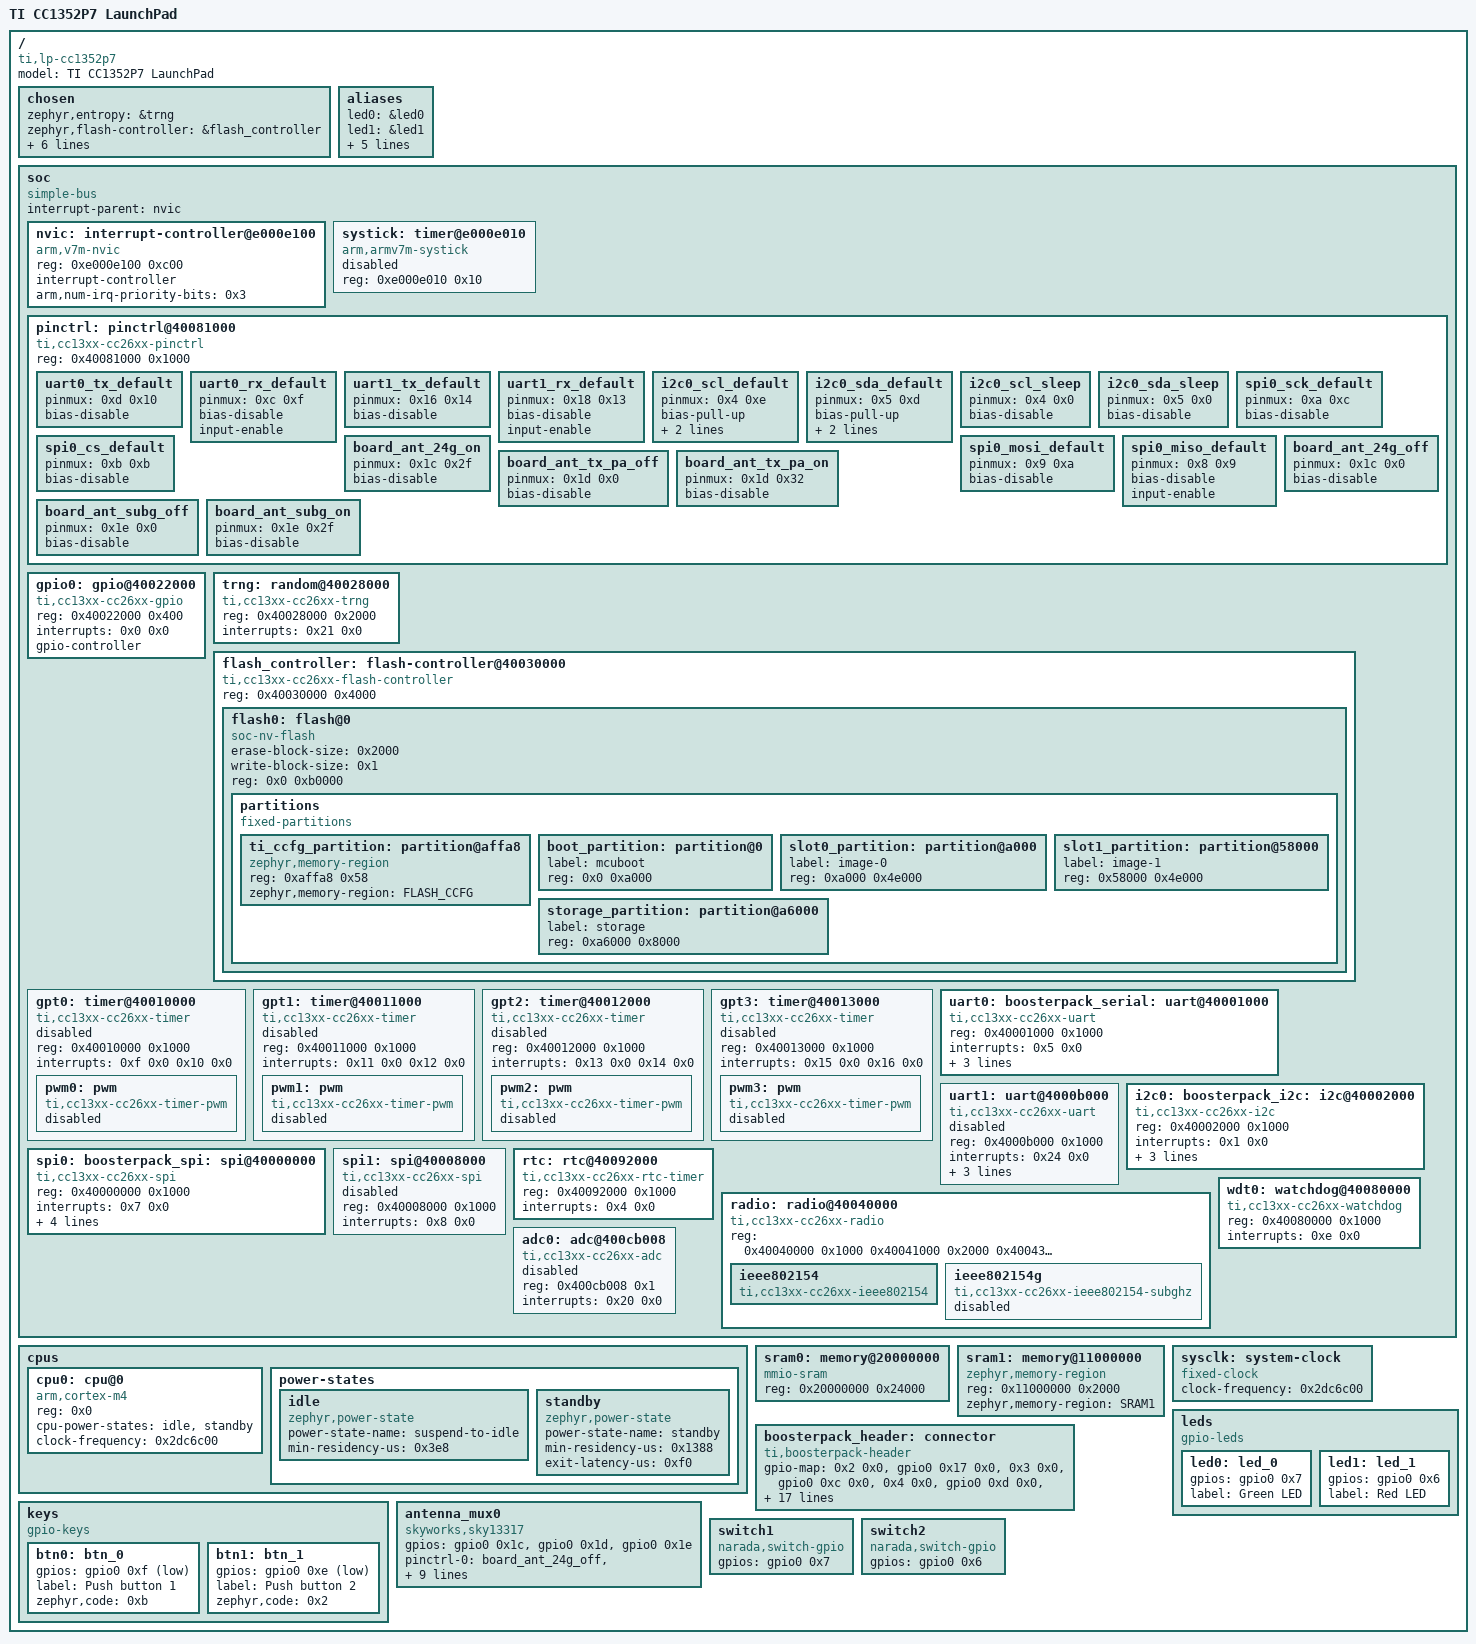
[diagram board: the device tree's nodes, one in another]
/dts-v1/;

/* node '/' defined in zephyr/dts/common/skeleton.dtsi:9 */
/ {
	#address-cells = < 0x1 >;        /* in zephyr/dts/common/skeleton.dtsi:10 */
	#size-cells = < 0x1 >;           /* in zephyr/dts/common/skeleton.dtsi:11 */
	model = "TI CC1352P7 LaunchPad"; /* in zephyr/boards/ti/cc1352p7_launchpad/cc1352p7_lp.dts:15 */
	compatible = "ti,lp-cc1352p7";   /* in zephyr/boards/ti/cc1352p7_launchpad/cc1352p7_lp.dts:16 */

	/* node '/chosen' defined in zephyr/dts/common/skeleton.dtsi:12 */
	chosen {
		zephyr,entropy = &trng;                      /* in zephyr/dts/arm/ti/cc13xx_cc26xx.dtsi:15 */
		zephyr,flash-controller = &flash_controller; /* in zephyr/dts/arm/ti/cc13xx_cc26xx.dtsi:16 */
		zephyr,sram = &sram0;                        /* in zephyr/boards/ti/common/launchxl.dtsi:25 */
		zephyr,flash = &flash0;                      /* in zephyr/boards/ti/common/launchxl.dtsi:26 */
		zephyr,console = &uart0;                     /* in zephyr/boards/ti/common/launchxl.dtsi:27 */
		zephyr,shell-uart = &uart0;                  /* in zephyr/boards/ti/common/launchxl.dtsi:28 */
		zephyr,ieee802154 = &ieee802154;             /* in zephyr/boards/ti/common/launchxl.dtsi:29 */
		zephyr,code-partition = &slot0_partition;    /* in zephyr/boards/ti/common/launchxl.dtsi:30 */
	};

	/* node '/aliases' defined in zephyr/dts/common/skeleton.dtsi:13 */
	aliases {
		led0 = &led0;            /* in zephyr/boards/ti/common/launchxl.dtsi:15 */
		led1 = &led1;            /* in zephyr/boards/ti/common/launchxl.dtsi:16 */
		sw0 = &btn0;             /* in zephyr/boards/ti/common/launchxl.dtsi:17 */
		sw1 = &btn1;             /* in zephyr/boards/ti/common/launchxl.dtsi:18 */
		watchdog0 = &wdt0;       /* in zephyr/boards/ti/common/launchxl.dtsi:19 */
		mcuboot-led0 = &led1;    /* in zephyr/boards/ti/common/launchxl.dtsi:20 */
		mcuboot-button0 = &btn1; /* in zephyr/boards/ti/common/launchxl.dtsi:21 */
	};

	/* node '/soc' defined in zephyr/dts/arm/armv7-m.dtsi:6 */
	soc {
		#address-cells = < 0x1 >;     /* in zephyr/dts/arm/armv7-m.dtsi:7 */
		#size-cells = < 0x1 >;        /* in zephyr/dts/arm/armv7-m.dtsi:8 */
		compatible = "simple-bus";    /* in zephyr/dts/arm/armv7-m.dtsi:9 */
		interrupt-parent = < &nvic >; /* in zephyr/dts/arm/armv7-m.dtsi:10 */
		ranges;                       /* in zephyr/dts/arm/armv7-m.dtsi:11 */

		/* node '/soc/interrupt-controller@e000e100' defined in zephyr/dts/arm/armv7-m.dtsi:13 */
		nvic: interrupt-controller@e000e100 {
			#address-cells = < 0x1 >;            /* in zephyr/dts/arm/armv7-m.dtsi:14 */
			compatible = "arm,v7m-nvic";         /* in zephyr/dts/arm/armv7-m.dtsi:15 */
			reg = < 0xe000e100 0xc00 >;          /* in zephyr/dts/arm/armv7-m.dtsi:16 */
			interrupt-controller;                /* in zephyr/dts/arm/armv7-m.dtsi:17 */
			#interrupt-cells = < 0x2 >;          /* in zephyr/dts/arm/armv7-m.dtsi:18 */
			arm,num-irq-priority-bits = < 0x3 >; /* in zephyr/dts/arm/ti/cc13xx_cc26xx.dtsi:246 */
			phandle = < 0x1 >;                   /* in zephyr/dts/arm/armv7-m.dtsi:10 */
		};

		/* node '/soc/timer@e000e010' defined in zephyr/dts/arm/armv7-m.dtsi:21 */
		systick: timer@e000e010 {
			compatible = "arm,armv7m-systick"; /* in zephyr/dts/arm/armv7-m.dtsi:22 */
			reg = < 0xe000e010 0x10 >;         /* in zephyr/dts/arm/armv7-m.dtsi:23 */
			status = "disabled";               /* in zephyr/dts/arm/ti/cc13xx_cc26xx.dtsi:250 */
		};

		/* node '/soc/pinctrl@40081000' defined in zephyr/dts/arm/ti/cc13xx_cc26xx.dtsi:64 */
		pinctrl: pinctrl@40081000 {
			compatible = "ti,cc13xx-cc26xx-pinctrl"; /* in zephyr/dts/arm/ti/cc13xx_cc26xx.dtsi:65 */
			reg = < 0x40081000 0x1000 >;             /* in zephyr/dts/arm/ti/cc13xx_cc26xx.dtsi:66 */

			/* node '/soc/pinctrl@40081000/uart0_tx_default' defined in zephyr/boards/ti/common/launchxl-pinctrl.dtsi:11 */
			uart0_tx_default: uart0_tx_default {
				pinmux = < 0xd 0x10 >; /* in zephyr/boards/ti/common/launchxl-pinctrl.dtsi:12 */
				bias-disable;          /* in zephyr/boards/ti/common/launchxl-pinctrl.dtsi:13 */
				phandle = < 0x4 >;     /* in zephyr/boards/ti/common/launchxl.dtsi:75 */
			};

			/* node '/soc/pinctrl@40081000/uart0_rx_default' defined in zephyr/boards/ti/common/launchxl-pinctrl.dtsi:15 */
			uart0_rx_default: uart0_rx_default {
				pinmux = < 0xc 0xf >; /* in zephyr/boards/ti/common/launchxl-pinctrl.dtsi:16 */
				bias-disable;         /* in zephyr/boards/ti/common/launchxl-pinctrl.dtsi:17 */
				input-enable;         /* in zephyr/boards/ti/common/launchxl-pinctrl.dtsi:18 */
				phandle = < 0x3 >;    /* in zephyr/boards/ti/common/launchxl.dtsi:75 */
			};

			/* node '/soc/pinctrl@40081000/uart1_tx_default' defined in zephyr/boards/ti/common/launchxl-pinctrl.dtsi:22 */
			uart1_tx_default: uart1_tx_default {
				pinmux = < 0x16 0x14 >; /* in zephyr/boards/ti/common/launchxl-pinctrl.dtsi:23 */
				bias-disable;           /* in zephyr/boards/ti/common/launchxl-pinctrl.dtsi:24 */
				phandle = < 0x6 >;      /* in zephyr/boards/ti/common/launchxl.dtsi:82 */
			};

			/* node '/soc/pinctrl@40081000/uart1_rx_default' defined in zephyr/boards/ti/common/launchxl-pinctrl.dtsi:26 */
			uart1_rx_default: uart1_rx_default {
				pinmux = < 0x18 0x13 >; /* in zephyr/boards/ti/common/launchxl-pinctrl.dtsi:27 */
				bias-disable;           /* in zephyr/boards/ti/common/launchxl-pinctrl.dtsi:28 */
				input-enable;           /* in zephyr/boards/ti/common/launchxl-pinctrl.dtsi:29 */
				phandle = < 0x5 >;      /* in zephyr/boards/ti/common/launchxl.dtsi:82 */
			};

			/* node '/soc/pinctrl@40081000/i2c0_scl_default' defined in zephyr/boards/ti/common/launchxl-pinctrl.dtsi:33 */
			i2c0_scl_default: i2c0_scl_default {
				pinmux = < 0x4 0xe >; /* in zephyr/boards/ti/common/launchxl-pinctrl.dtsi:34 */
				bias-pull-up;         /* in zephyr/boards/ti/common/launchxl-pinctrl.dtsi:35 */
				drive-open-drain;     /* in zephyr/boards/ti/common/launchxl-pinctrl.dtsi:36 */
				input-enable;         /* in zephyr/boards/ti/common/launchxl-pinctrl.dtsi:37 */
				phandle = < 0x7 >;    /* in zephyr/boards/ti/common/launchxl.dtsi:88 */
			};

			/* node '/soc/pinctrl@40081000/i2c0_sda_default' defined in zephyr/boards/ti/common/launchxl-pinctrl.dtsi:39 */
			i2c0_sda_default: i2c0_sda_default {
				pinmux = < 0x5 0xd >; /* in zephyr/boards/ti/common/launchxl-pinctrl.dtsi:40 */
				bias-pull-up;         /* in zephyr/boards/ti/common/launchxl-pinctrl.dtsi:41 */
				drive-open-drain;     /* in zephyr/boards/ti/common/launchxl-pinctrl.dtsi:42 */
				input-enable;         /* in zephyr/boards/ti/common/launchxl-pinctrl.dtsi:43 */
				phandle = < 0x8 >;    /* in zephyr/boards/ti/common/launchxl.dtsi:88 */
			};

			/* node '/soc/pinctrl@40081000/i2c0_scl_sleep' defined in zephyr/boards/ti/common/launchxl-pinctrl.dtsi:45 */
			i2c0_scl_sleep: i2c0_scl_sleep {
				pinmux = < 0x4 0x0 >; /* in zephyr/boards/ti/common/launchxl-pinctrl.dtsi:46 */
				bias-disable;         /* in zephyr/boards/ti/common/launchxl-pinctrl.dtsi:47 */
				phandle = < 0x9 >;    /* in zephyr/boards/ti/common/launchxl.dtsi:89 */
			};

			/* node '/soc/pinctrl@40081000/i2c0_sda_sleep' defined in zephyr/boards/ti/common/launchxl-pinctrl.dtsi:49 */
			i2c0_sda_sleep: i2c0_sda_sleep {
				pinmux = < 0x5 0x0 >; /* in zephyr/boards/ti/common/launchxl-pinctrl.dtsi:50 */
				bias-disable;         /* in zephyr/boards/ti/common/launchxl-pinctrl.dtsi:51 */
				phandle = < 0xa >;    /* in zephyr/boards/ti/common/launchxl.dtsi:89 */
			};

			/* node '/soc/pinctrl@40081000/spi0_sck_default' defined in zephyr/boards/ti/common/launchxl-pinctrl.dtsi:55 */
			spi0_sck_default: spi0_sck_default {
				pinmux = < 0xa 0xc >; /* in zephyr/boards/ti/common/launchxl-pinctrl.dtsi:56 */
				bias-disable;         /* in zephyr/boards/ti/common/launchxl-pinctrl.dtsi:57 */
				phandle = < 0xb >;    /* in zephyr/boards/ti/common/launchxl.dtsi:95 */
			};

			/* node '/soc/pinctrl@40081000/spi0_mosi_default' defined in zephyr/boards/ti/common/launchxl-pinctrl.dtsi:59 */
			spi0_mosi_default: spi0_mosi_default {
				pinmux = < 0x9 0xa >; /* in zephyr/boards/ti/common/launchxl-pinctrl.dtsi:60 */
				bias-disable;         /* in zephyr/boards/ti/common/launchxl-pinctrl.dtsi:61 */
				phandle = < 0xc >;    /* in zephyr/boards/ti/common/launchxl.dtsi:95 */
			};

			/* node '/soc/pinctrl@40081000/spi0_miso_default' defined in zephyr/boards/ti/common/launchxl-pinctrl.dtsi:63 */
			spi0_miso_default: spi0_miso_default {
				pinmux = < 0x8 0x9 >; /* in zephyr/boards/ti/common/launchxl-pinctrl.dtsi:64 */
				bias-disable;         /* in zephyr/boards/ti/common/launchxl-pinctrl.dtsi:65 */
				input-enable;         /* in zephyr/boards/ti/common/launchxl-pinctrl.dtsi:66 */
				phandle = < 0xd >;    /* in zephyr/boards/ti/common/launchxl.dtsi:95 */
			};

			/* node '/soc/pinctrl@40081000/spi0_cs_default' defined in zephyr/boards/ti/common/launchxl-pinctrl.dtsi:68 */
			spi0_cs_default: spi0_cs_default {
				pinmux = < 0xb 0xb >; /* in zephyr/boards/ti/common/launchxl-pinctrl.dtsi:69 */
				bias-disable;         /* in zephyr/boards/ti/common/launchxl-pinctrl.dtsi:70 */
				phandle = < 0xe >;    /* in zephyr/boards/ti/common/launchxl.dtsi:95 */
			};

			/* node '/soc/pinctrl@40081000/board_ant_24g_off' defined in zephyr/boards/ti/common/launchxl_sky13317.dtsi:37 */
			board_ant_24g_off: board_ant_24g_off {
				pinmux = < 0x1c 0x0 >; /* in zephyr/boards/ti/common/launchxl_sky13317.dtsi:38 */
				bias-disable;          /* in zephyr/boards/ti/common/launchxl_sky13317.dtsi:39 */
				phandle = < 0x12 >;    /* in zephyr/boards/ti/common/launchxl_sky13317.dtsi:26 */
			};

			/* node '/soc/pinctrl@40081000/board_ant_24g_on' defined in zephyr/boards/ti/common/launchxl_sky13317.dtsi:41 */
			board_ant_24g_on: board_ant_24g_on {
				pinmux = < 0x1c 0x2f >; /* in zephyr/boards/ti/common/launchxl_sky13317.dtsi:42 */
				bias-disable;           /* in zephyr/boards/ti/common/launchxl_sky13317.dtsi:43 */
				phandle = < 0x15 >;     /* in zephyr/boards/ti/common/launchxl_sky13317.dtsi:27 */
			};

			/* node '/soc/pinctrl@40081000/board_ant_tx_pa_off' defined in zephyr/boards/ti/common/launchxl_sky13317.dtsi:45 */
			board_ant_tx_pa_off: board_ant_tx_pa_off {
				pinmux = < 0x1d 0x0 >; /* in zephyr/boards/ti/common/launchxl_sky13317.dtsi:46 */
				bias-disable;          /* in zephyr/boards/ti/common/launchxl_sky13317.dtsi:47 */
				phandle = < 0x13 >;    /* in zephyr/boards/ti/common/launchxl_sky13317.dtsi:26 */
			};

			/* node '/soc/pinctrl@40081000/board_ant_tx_pa_on' defined in zephyr/boards/ti/common/launchxl_sky13317.dtsi:49 */
			board_ant_tx_pa_on: board_ant_tx_pa_on {
				pinmux = < 0x1d 0x32 >; /* in zephyr/boards/ti/common/launchxl_sky13317.dtsi:50 */
				bias-disable;           /* in zephyr/boards/ti/common/launchxl_sky13317.dtsi:51 */
				phandle = < 0x16 >;     /* in zephyr/boards/ti/common/launchxl_sky13317.dtsi:28 */
			};

			/* node '/soc/pinctrl@40081000/board_ant_subg_off' defined in zephyr/boards/ti/common/launchxl_sky13317.dtsi:53 */
			board_ant_subg_off: board_ant_subg_off {
				pinmux = < 0x1e 0x0 >; /* in zephyr/boards/ti/common/launchxl_sky13317.dtsi:54 */
				bias-disable;          /* in zephyr/boards/ti/common/launchxl_sky13317.dtsi:55 */
				phandle = < 0x14 >;    /* in zephyr/boards/ti/common/launchxl_sky13317.dtsi:26 */
			};

			/* node '/soc/pinctrl@40081000/board_ant_subg_on' defined in zephyr/boards/ti/common/launchxl_sky13317.dtsi:57 */
			board_ant_subg_on: board_ant_subg_on {
				pinmux = < 0x1e 0x2f >; /* in zephyr/boards/ti/common/launchxl_sky13317.dtsi:58 */
				bias-disable;           /* in zephyr/boards/ti/common/launchxl_sky13317.dtsi:59 */
				phandle = < 0x17 >;     /* in zephyr/boards/ti/common/launchxl_sky13317.dtsi:29 */
			};
		};

		/* node '/soc/gpio@40022000' defined in zephyr/dts/arm/ti/cc13xx_cc26xx.dtsi:69 */
		gpio0: gpio@40022000 {
			compatible = "ti,cc13xx-cc26xx-gpio"; /* in zephyr/dts/arm/ti/cc13xx_cc26xx.dtsi:70 */
			reg = < 0x40022000 0x400 >;           /* in zephyr/dts/arm/ti/cc13xx_cc26xx.dtsi:71 */
			interrupts = < 0x0 0x0 >;             /* in zephyr/dts/arm/ti/cc13xx_cc26xx.dtsi:72 */
			status = "okay";                      /* in zephyr/boards/ti/common/launchxl.dtsi:69 */
			gpio-controller;                      /* in zephyr/dts/arm/ti/cc13xx_cc26xx.dtsi:74 */
			#gpio-cells = < 0x2 >;                /* in zephyr/dts/arm/ti/cc13xx_cc26xx.dtsi:75 */
			phandle = < 0xf >;                    /* in zephyr/boards/ti/common/launchxl.dtsi:98 */
		};

		/* node '/soc/random@40028000' defined in zephyr/dts/arm/ti/cc13xx_cc26xx.dtsi:78 */
		trng: random@40028000 {
			compatible = "ti,cc13xx-cc26xx-trng"; /* in zephyr/dts/arm/ti/cc13xx_cc26xx.dtsi:79 */
			reg = < 0x40028000 0x2000 >;          /* in zephyr/dts/arm/ti/cc13xx_cc26xx.dtsi:80 */
			interrupts = < 0x21 0x0 >;            /* in zephyr/dts/arm/ti/cc13xx_cc26xx.dtsi:81 */
			status = "okay";                      /* in zephyr/boards/ti/common/launchxl.dtsi:65 */
		};

		/* node '/soc/flash-controller@40030000' defined in zephyr/dts/arm/ti/cc13xx_cc26xx.dtsi:85 */
		flash_controller: flash-controller@40030000 {
			compatible = "ti,cc13xx-cc26xx-flash-controller"; /* in zephyr/dts/arm/ti/cc13xx_cc26xx.dtsi:86 */
			reg = < 0x40030000 0x4000 >;                      /* in zephyr/dts/arm/ti/cc13xx_cc26xx.dtsi:87 */
			#address-cells = < 0x1 >;                         /* in zephyr/dts/arm/ti/cc13xx_cc26xx.dtsi:89 */
			#size-cells = < 0x1 >;                            /* in zephyr/dts/arm/ti/cc13xx_cc26xx.dtsi:90 */

			/* node '/soc/flash-controller@40030000/flash@0' defined in zephyr/dts/arm/ti/cc13xx_cc26xx.dtsi:92 */
			flash0: flash@0 {
				compatible = "soc-nv-flash";   /* in zephyr/dts/arm/ti/cc13xx_cc26xx.dtsi:93 */
				erase-block-size = < 0x2000 >; /* in zephyr/dts/arm/ti/cc13xx_cc26xx.dtsi:94 */
				write-block-size = < 0x1 >;    /* in zephyr/dts/arm/ti/cc13xx_cc26xx.dtsi:95 */
				reg = < 0x0 0xb0000 >;         /* in zephyr/dts/arm/ti/cc1352r7.dtsi:17 */

				/* node '/soc/flash-controller@40030000/flash@0/partitions' defined in zephyr/dts/arm/ti/cc1352r7.dtsi:19 */
				partitions {
					compatible = "fixed-partitions"; /* in zephyr/dts/arm/ti/cc1352r7.dtsi:20 */
					#address-cells = < 0x1 >;        /* in zephyr/dts/arm/ti/cc1352r7.dtsi:21 */
					#size-cells = < 0x1 >;           /* in zephyr/dts/arm/ti/cc1352r7.dtsi:22 */

					/* node '/soc/flash-controller@40030000/flash@0/partitions/partition@affa8' defined in zephyr/dts/arm/ti/cc1352r7.dtsi:25 */
					ti_ccfg_partition: partition@affa8 {
						compatible = "zephyr,memory-region"; /* in zephyr/dts/arm/ti/cc1352r7.dtsi:26 */
						reg = < 0xaffa8 0x58 >;              /* in zephyr/dts/arm/ti/cc1352r7.dtsi:27 */
						zephyr,memory-region = "FLASH_CCFG"; /* in zephyr/dts/arm/ti/cc1352r7.dtsi:28 */
					};

					/* node '/soc/flash-controller@40030000/flash@0/partitions/partition@0' defined in zephyr/boards/ti/common/launchxl-flash-p7.dtsi:10 */
					boot_partition: partition@0 {
						label = "mcuboot";    /* in zephyr/boards/ti/common/launchxl-flash-p7.dtsi:11 */
						reg = < 0x0 0xa000 >; /* in zephyr/boards/ti/common/launchxl-flash-p7.dtsi:12 */
					};

					/* node '/soc/flash-controller@40030000/flash@0/partitions/partition@a000' defined in zephyr/boards/ti/common/launchxl-flash-p7.dtsi:16 */
					slot0_partition: partition@a000 {
						label = "image-0";        /* in zephyr/boards/ti/common/launchxl-flash-p7.dtsi:17 */
						reg = < 0xa000 0x4e000 >; /* in zephyr/boards/ti/common/launchxl-flash-p7.dtsi:18 */
					};

					/* node '/soc/flash-controller@40030000/flash@0/partitions/partition@58000' defined in zephyr/boards/ti/common/launchxl-flash-p7.dtsi:21 */
					slot1_partition: partition@58000 {
						label = "image-1";         /* in zephyr/boards/ti/common/launchxl-flash-p7.dtsi:22 */
						reg = < 0x58000 0x4e000 >; /* in zephyr/boards/ti/common/launchxl-flash-p7.dtsi:23 */
					};

					/* node '/soc/flash-controller@40030000/flash@0/partitions/partition@a6000' defined in zephyr/boards/ti/common/launchxl-flash-p7.dtsi:27 */
					storage_partition: partition@a6000 {
						label = "storage";        /* in zephyr/boards/ti/common/launchxl-flash-p7.dtsi:28 */
						reg = < 0xa6000 0x8000 >; /* in zephyr/boards/ti/common/launchxl-flash-p7.dtsi:29 */
					};
				};
			};
		};

		/* node '/soc/timer@40010000' defined in zephyr/dts/arm/ti/cc13xx_cc26xx.dtsi:99 */
		gpt0: timer@40010000 {
			compatible = "ti,cc13xx-cc26xx-timer"; /* in zephyr/dts/arm/ti/cc13xx_cc26xx.dtsi:100 */
			reg = < 0x40010000 0x1000 >;           /* in zephyr/dts/arm/ti/cc13xx_cc26xx.dtsi:101 */
			interrupts = < 0xf 0x0 0x10 0x0 >;     /* in zephyr/dts/arm/ti/cc13xx_cc26xx.dtsi:102 */
			interrupt-names = "gpt0a",
			                  "gpt0b";             /* in zephyr/dts/arm/ti/cc13xx_cc26xx.dtsi:103 */
			status = "disabled";                   /* in zephyr/dts/arm/ti/cc13xx_cc26xx.dtsi:104 */

			/* node '/soc/timer@40010000/pwm' defined in zephyr/dts/arm/ti/cc13xx_cc26xx.dtsi:106 */
			pwm0: pwm {
				compatible = "ti,cc13xx-cc26xx-timer-pwm"; /* in zephyr/dts/arm/ti/cc13xx_cc26xx.dtsi:107 */
				#pwm-cells = < 0x3 >;                      /* in zephyr/dts/arm/ti/cc13xx_cc26xx.dtsi:108 */
				status = "disabled";                       /* in zephyr/dts/arm/ti/cc13xx_cc26xx.dtsi:109 */
			};
		};

		/* node '/soc/timer@40011000' defined in zephyr/dts/arm/ti/cc13xx_cc26xx.dtsi:113 */
		gpt1: timer@40011000 {
			compatible = "ti,cc13xx-cc26xx-timer"; /* in zephyr/dts/arm/ti/cc13xx_cc26xx.dtsi:114 */
			reg = < 0x40011000 0x1000 >;           /* in zephyr/dts/arm/ti/cc13xx_cc26xx.dtsi:115 */
			interrupts = < 0x11 0x0 0x12 0x0 >;    /* in zephyr/dts/arm/ti/cc13xx_cc26xx.dtsi:116 */
			interrupt-names = "gpt1a",
			                  "gpt1b";             /* in zephyr/dts/arm/ti/cc13xx_cc26xx.dtsi:117 */
			status = "disabled";                   /* in zephyr/dts/arm/ti/cc13xx_cc26xx.dtsi:118 */

			/* node '/soc/timer@40011000/pwm' defined in zephyr/dts/arm/ti/cc13xx_cc26xx.dtsi:120 */
			pwm1: pwm {
				compatible = "ti,cc13xx-cc26xx-timer-pwm"; /* in zephyr/dts/arm/ti/cc13xx_cc26xx.dtsi:121 */
				#pwm-cells = < 0x3 >;                      /* in zephyr/dts/arm/ti/cc13xx_cc26xx.dtsi:122 */
				status = "disabled";                       /* in zephyr/dts/arm/ti/cc13xx_cc26xx.dtsi:123 */
			};
		};

		/* node '/soc/timer@40012000' defined in zephyr/dts/arm/ti/cc13xx_cc26xx.dtsi:127 */
		gpt2: timer@40012000 {
			compatible = "ti,cc13xx-cc26xx-timer"; /* in zephyr/dts/arm/ti/cc13xx_cc26xx.dtsi:128 */
			reg = < 0x40012000 0x1000 >;           /* in zephyr/dts/arm/ti/cc13xx_cc26xx.dtsi:129 */
			interrupts = < 0x13 0x0 0x14 0x0 >;    /* in zephyr/dts/arm/ti/cc13xx_cc26xx.dtsi:130 */
			interrupt-names = "gpt2a",
			                  "gpt2b";             /* in zephyr/dts/arm/ti/cc13xx_cc26xx.dtsi:131 */
			status = "disabled";                   /* in zephyr/dts/arm/ti/cc13xx_cc26xx.dtsi:132 */

			/* node '/soc/timer@40012000/pwm' defined in zephyr/dts/arm/ti/cc13xx_cc26xx.dtsi:134 */
			pwm2: pwm {
				compatible = "ti,cc13xx-cc26xx-timer-pwm"; /* in zephyr/dts/arm/ti/cc13xx_cc26xx.dtsi:135 */
				#pwm-cells = < 0x3 >;                      /* in zephyr/dts/arm/ti/cc13xx_cc26xx.dtsi:136 */
				status = "disabled";                       /* in zephyr/dts/arm/ti/cc13xx_cc26xx.dtsi:137 */
			};
		};

		/* node '/soc/timer@40013000' defined in zephyr/dts/arm/ti/cc13xx_cc26xx.dtsi:141 */
		gpt3: timer@40013000 {
			compatible = "ti,cc13xx-cc26xx-timer"; /* in zephyr/dts/arm/ti/cc13xx_cc26xx.dtsi:142 */
			reg = < 0x40013000 0x1000 >;           /* in zephyr/dts/arm/ti/cc13xx_cc26xx.dtsi:143 */
			interrupts = < 0x15 0x0 0x16 0x0 >;    /* in zephyr/dts/arm/ti/cc13xx_cc26xx.dtsi:144 */
			interrupt-names = "gpt3a",
			                  "gpt3b";             /* in zephyr/dts/arm/ti/cc13xx_cc26xx.dtsi:145 */
			status = "disabled";                   /* in zephyr/dts/arm/ti/cc13xx_cc26xx.dtsi:146 */

			/* node '/soc/timer@40013000/pwm' defined in zephyr/dts/arm/ti/cc13xx_cc26xx.dtsi:148 */
			pwm3: pwm {
				compatible = "ti,cc13xx-cc26xx-timer-pwm"; /* in zephyr/dts/arm/ti/cc13xx_cc26xx.dtsi:149 */
				#pwm-cells = < 0x3 >;                      /* in zephyr/dts/arm/ti/cc13xx_cc26xx.dtsi:150 */
				status = "disabled";                       /* in zephyr/dts/arm/ti/cc13xx_cc26xx.dtsi:151 */
			};
		};

		/* node '/soc/uart@40001000' defined in zephyr/dts/arm/ti/cc13xx_cc26xx.dtsi:155 */
		uart0: boosterpack_serial: uart@40001000 {
			compatible = "ti,cc13xx-cc26xx-uart";                /* in zephyr/dts/arm/ti/cc13xx_cc26xx.dtsi:156 */
			reg = < 0x40001000 0x1000 >;                         /* in zephyr/dts/arm/ti/cc13xx_cc26xx.dtsi:157 */
			interrupts = < 0x5 0x0 >;                            /* in zephyr/dts/arm/ti/cc13xx_cc26xx.dtsi:158 */
			clocks = < &sysclk >;                                /* in zephyr/dts/arm/ti/cc13xx_cc26xx.dtsi:159 */
			status = "okay";                                     /* in zephyr/boards/ti/common/launchxl.dtsi:73 */
			current-speed = < 0x1c200 >;                         /* in zephyr/boards/ti/common/launchxl.dtsi:74 */
			pinctrl-0 = < &uart0_rx_default &uart0_tx_default >; /* in zephyr/boards/ti/common/launchxl.dtsi:75 */
			pinctrl-names = "default";                           /* in zephyr/boards/ti/common/launchxl.dtsi:76 */
		};

		/* node '/soc/uart@4000b000' defined in zephyr/dts/arm/ti/cc13xx_cc26xx.dtsi:163 */
		uart1: uart@4000b000 {
			compatible = "ti,cc13xx-cc26xx-uart";                /* in zephyr/dts/arm/ti/cc13xx_cc26xx.dtsi:164 */
			reg = < 0x4000b000 0x1000 >;                         /* in zephyr/dts/arm/ti/cc13xx_cc26xx.dtsi:165 */
			interrupts = < 0x24 0x0 >;                           /* in zephyr/dts/arm/ti/cc13xx_cc26xx.dtsi:166 */
			clocks = < &sysclk >;                                /* in zephyr/dts/arm/ti/cc13xx_cc26xx.dtsi:167 */
			status = "disabled";                                 /* in zephyr/boards/ti/common/launchxl.dtsi:80 */
			current-speed = < 0x1c200 >;                         /* in zephyr/boards/ti/common/launchxl.dtsi:81 */
			pinctrl-0 = < &uart1_rx_default &uart1_tx_default >; /* in zephyr/boards/ti/common/launchxl.dtsi:82 */
			pinctrl-names = "default";                           /* in zephyr/boards/ti/common/launchxl.dtsi:83 */
		};

		/* node '/soc/i2c@40002000' defined in zephyr/dts/arm/ti/cc13xx_cc26xx.dtsi:171 */
		i2c0: boosterpack_i2c: i2c@40002000 {
			compatible = "ti,cc13xx-cc26xx-i2c";                 /* in zephyr/dts/arm/ti/cc13xx_cc26xx.dtsi:172 */
			#address-cells = < 0x1 >;                            /* in zephyr/dts/arm/ti/cc13xx_cc26xx.dtsi:173 */
			#size-cells = < 0x0 >;                               /* in zephyr/dts/arm/ti/cc13xx_cc26xx.dtsi:174 */
			reg = < 0x40002000 0x1000 >;                         /* in zephyr/dts/arm/ti/cc13xx_cc26xx.dtsi:175 */
			interrupts = < 0x1 0x0 >;                            /* in zephyr/dts/arm/ti/cc13xx_cc26xx.dtsi:176 */
			clock-frequency = < 0x186a0 >;                       /* in zephyr/dts/arm/ti/cc13xx_cc26xx.dtsi:177 */
			status = "okay";                                     /* in zephyr/boards/ti/common/launchxl.dtsi:87 */
			pinctrl-0 = < &i2c0_scl_default &i2c0_sda_default >; /* in zephyr/boards/ti/common/launchxl.dtsi:88 */
			pinctrl-1 = < &i2c0_scl_sleep &i2c0_sda_sleep >;     /* in zephyr/boards/ti/common/launchxl.dtsi:89 */
			pinctrl-names = "default",
			                "sleep";                             /* in zephyr/boards/ti/common/launchxl.dtsi:90 */
		};

		/* node '/soc/spi@40000000' defined in zephyr/dts/arm/ti/cc13xx_cc26xx.dtsi:181 */
		spi0: boosterpack_spi: spi@40000000 {
			compatible = "ti,cc13xx-cc26xx-spi";                                                      /* in zephyr/dts/arm/ti/cc13xx_cc26xx.dtsi:182 */
			#address-cells = < 0x1 >;                                                                 /* in zephyr/dts/arm/ti/cc13xx_cc26xx.dtsi:183 */
			#size-cells = < 0x0 >;                                                                    /* in zephyr/dts/arm/ti/cc13xx_cc26xx.dtsi:184 */
			reg = < 0x40000000 0x1000 >;                                                              /* in zephyr/dts/arm/ti/cc13xx_cc26xx.dtsi:185 */
			interrupts = < 0x7 0x0 >;                                                                 /* in zephyr/dts/arm/ti/cc13xx_cc26xx.dtsi:186 */
			status = "okay";                                                                          /* in zephyr/boards/ti/common/launchxl.dtsi:94 */
			pinctrl-0 = < &spi0_sck_default &spi0_mosi_default &spi0_miso_default &spi0_cs_default >; /* in zephyr/boards/ti/common/launchxl.dtsi:95 */
			pinctrl-names = "default";                                                                /* in zephyr/boards/ti/common/launchxl.dtsi:97 */
			cs-gpios = < &gpio0 0xb 0x1 >;                                                            /* in zephyr/boards/ti/common/launchxl.dtsi:98 */
		};

		/* node '/soc/spi@40008000' defined in zephyr/dts/arm/ti/cc13xx_cc26xx.dtsi:190 */
		spi1: spi@40008000 {
			compatible = "ti,cc13xx-cc26xx-spi"; /* in zephyr/dts/arm/ti/cc13xx_cc26xx.dtsi:191 */
			#address-cells = < 0x1 >;            /* in zephyr/dts/arm/ti/cc13xx_cc26xx.dtsi:192 */
			#size-cells = < 0x0 >;               /* in zephyr/dts/arm/ti/cc13xx_cc26xx.dtsi:193 */
			reg = < 0x40008000 0x1000 >;         /* in zephyr/dts/arm/ti/cc13xx_cc26xx.dtsi:194 */
			interrupts = < 0x8 0x0 >;            /* in zephyr/dts/arm/ti/cc13xx_cc26xx.dtsi:195 */
			status = "disabled";                 /* in zephyr/dts/arm/ti/cc13xx_cc26xx.dtsi:196 */
		};

		/* node '/soc/rtc@40092000' defined in zephyr/dts/arm/ti/cc13xx_cc26xx.dtsi:200 */
		rtc: rtc@40092000 {
			compatible = "ti,cc13xx-cc26xx-rtc-timer"; /* in zephyr/dts/arm/ti/cc13xx_cc26xx.dtsi:201 */
			reg = < 0x40092000 0x1000 >;               /* in zephyr/dts/arm/ti/cc13xx_cc26xx.dtsi:202 */
			interrupts = < 0x4 0x0 >;                  /* in zephyr/dts/arm/ti/cc13xx_cc26xx.dtsi:203 */
			status = "okay";                           /* in zephyr/dts/arm/ti/cc13xx_cc26xx.dtsi:204 */
		};

		/* node '/soc/radio@40040000' defined in zephyr/dts/arm/ti/cc13xx_cc26xx.dtsi:207 */
		radio: radio@40040000 {
			compatible = "ti,cc13xx-cc26xx-radio";                                             /* in zephyr/dts/arm/ti/cc13xx_cc26xx.dtsi:208 */
			status = "okay";                                                                   /* in zephyr/boards/ti/common/launchxl.dtsi:102 */
			reg = < 0x40040000 0x1000 0x40041000 0x2000 0x40043000 0x1000 0x40044000 0x1000 >; /* in zephyr/dts/arm/ti/cc13xx_cc26xx.dtsi:211 */
			reg-names = "RFC_PWR",
			            "RFC_DBELL",
			            "RFC_RAT",
			            "RFC_FSCA";                                                            /* in zephyr/dts/arm/ti/cc13xx_cc26xx.dtsi:215 */

			/* node '/soc/radio@40040000/ieee802154' defined in zephyr/dts/arm/ti/cc13xx_cc26xx.dtsi:217 */
			ieee802154: ieee802154 {
				compatible = "ti,cc13xx-cc26xx-ieee802154"; /* in zephyr/dts/arm/ti/cc13xx_cc26xx.dtsi:218 */
				status = "okay";                            /* in zephyr/boards/ti/common/launchxl.dtsi:106 */
			};

			/* node '/soc/radio@40040000/ieee802154g' defined in zephyr/dts/arm/ti/cc13xx_cc26xx.dtsi:222 */
			ieee802154g: ieee802154g {
				compatible = "ti,cc13xx-cc26xx-ieee802154-subghz"; /* in zephyr/dts/arm/ti/cc13xx_cc26xx.dtsi:223 */
				status = "disabled";                               /* in zephyr/boards/ti/common/launchxl.dtsi:110 */
			};
		};

		/* node '/soc/watchdog@40080000' defined in zephyr/dts/arm/ti/cc13xx_cc26xx.dtsi:228 */
		wdt0: watchdog@40080000 {
			compatible = "ti,cc13xx-cc26xx-watchdog"; /* in zephyr/dts/arm/ti/cc13xx_cc26xx.dtsi:229 */
			reg = < 0x40080000 0x1000 >;              /* in zephyr/dts/arm/ti/cc13xx_cc26xx.dtsi:230 */
			interrupts = < 0xe 0x0 >;                 /* in zephyr/dts/arm/ti/cc13xx_cc26xx.dtsi:231 */
			status = "okay";                          /* in zephyr/boards/ti/common/launchxl.dtsi:114 */
		};

		/* node '/soc/adc@400cb008' defined in zephyr/dts/arm/ti/cc13xx_cc26xx.dtsi:235 */
		adc0: adc@400cb008 {
			compatible = "ti,cc13xx-cc26xx-adc"; /* in zephyr/dts/arm/ti/cc13xx_cc26xx.dtsi:236 */
			reg = < 0x400cb008 0x1 >;            /* in zephyr/dts/arm/ti/cc13xx_cc26xx.dtsi:237 */
			interrupts = < 0x20 0x0 >;           /* in zephyr/dts/arm/ti/cc13xx_cc26xx.dtsi:238 */
			status = "disabled";                 /* in zephyr/dts/arm/ti/cc13xx_cc26xx.dtsi:239 */
			#io-channel-cells = < 0x1 >;         /* in zephyr/dts/arm/ti/cc13xx_cc26xx.dtsi:240 */
		};
	};

	/* node '/cpus' defined in zephyr/dts/arm/ti/cc13xx_cc26xx.dtsi:19 */
	cpus {
		#address-cells = < 0x1 >; /* in zephyr/dts/arm/ti/cc13xx_cc26xx.dtsi:20 */
		#size-cells = < 0x0 >;    /* in zephyr/dts/arm/ti/cc13xx_cc26xx.dtsi:21 */

		/* node '/cpus/cpu@0' defined in zephyr/dts/arm/ti/cc13xx_cc26xx.dtsi:23 */
		cpu0: cpu@0 {
			device_type = "cpu";                   /* in zephyr/dts/arm/ti/cc13xx_cc26xx.dtsi:24 */
			compatible = "arm,cortex-m4";          /* in zephyr/dts/arm/ti/cc13xx_cc26xx.dtsi:25 */
			reg = < 0x0 >;                         /* in zephyr/dts/arm/ti/cc13xx_cc26xx.dtsi:26 */
			cpu-power-states = < &idle &standby >; /* in zephyr/dts/arm/ti/cc13xx_cc26xx.dtsi:27 */
			clock-frequency = < 0x2dc6c00 >;       /* in zephyr/boards/ti/common/launchxl.dtsi:61 */
		};

		/* node '/cpus/power-states' defined in zephyr/dts/arm/ti/cc13xx_cc26xx.dtsi:30 */
		power-states {

			/* node '/cpus/power-states/idle' defined in zephyr/dts/arm/ti/cc13xx_cc26xx.dtsi:31 */
			idle: idle {
				compatible = "zephyr,power-state";    /* in zephyr/dts/arm/ti/cc13xx_cc26xx.dtsi:32 */
				power-state-name = "suspend-to-idle"; /* in zephyr/dts/arm/ti/cc13xx_cc26xx.dtsi:33 */
				min-residency-us = < 0x3e8 >;         /* in zephyr/dts/arm/ti/cc13xx_cc26xx.dtsi:34 */
				phandle = < 0x10 >;                   /* in zephyr/dts/arm/ti/cc13xx_cc26xx.dtsi:27 */
			};

			/* node '/cpus/power-states/standby' defined in zephyr/dts/arm/ti/cc13xx_cc26xx.dtsi:37 */
			standby: standby {
				compatible = "zephyr,power-state"; /* in zephyr/dts/arm/ti/cc13xx_cc26xx.dtsi:38 */
				power-state-name = "standby";      /* in zephyr/dts/arm/ti/cc13xx_cc26xx.dtsi:39 */
				min-residency-us = < 0x1388 >;     /* in zephyr/dts/arm/ti/cc13xx_cc26xx.dtsi:40 */
				exit-latency-us = < 0xf0 >;        /* in zephyr/dts/arm/ti/cc13xx_cc26xx.dtsi:41 */
				phandle = < 0x11 >;                /* in zephyr/dts/arm/ti/cc13xx_cc26xx.dtsi:27 */
			};
		};
	};

	/* node '/memory@20000000' defined in zephyr/dts/arm/ti/cc13xx_cc26xx.dtsi:46 */
	sram0: memory@20000000 {
		compatible = "mmio-sram";     /* in zephyr/dts/arm/ti/cc13xx_cc26xx.dtsi:47 */
		reg = < 0x20000000 0x24000 >; /* in zephyr/dts/arm/ti/cc1352r7.dtsi:12 */
	};

	/* node '/memory@11000000' defined in zephyr/dts/arm/ti/cc13xx_cc26xx.dtsi:51 */
	sram1: memory@11000000 {
		compatible = "zephyr,memory-region",
		             "mmio-sram";            /* in zephyr/dts/arm/ti/cc13xx_cc26xx.dtsi:52 */
		reg = < 0x11000000 0x2000 >;         /* in zephyr/dts/arm/ti/cc13xx_cc26xx.dtsi:53 */
		zephyr,memory-region = "SRAM1";      /* in zephyr/dts/arm/ti/cc13xx_cc26xx.dtsi:54 */
	};

	/* node '/system-clock' defined in zephyr/dts/arm/ti/cc13xx_cc26xx.dtsi:57 */
	sysclk: system-clock {
		compatible = "fixed-clock";      /* in zephyr/dts/arm/ti/cc13xx_cc26xx.dtsi:58 */
		clock-frequency = < 0x2dc6c00 >; /* in zephyr/dts/arm/ti/cc13xx_cc26xx.dtsi:59 */
		#clock-cells = < 0x0 >;          /* in zephyr/dts/arm/ti/cc13xx_cc26xx.dtsi:60 */
		phandle = < 0x2 >;               /* in zephyr/dts/arm/ti/cc13xx_cc26xx.dtsi:159 */
	};

	/* node '/connector' defined in zephyr/boards/ti/common/boosterpack_connector.dtsi:8 */
	boosterpack_header: connector {
		compatible = "ti,boosterpack-header";    /* in zephyr/boards/ti/common/boosterpack_connector.dtsi:9 */
		#gpio-cells = < 0x2 >;                   /* in zephyr/boards/ti/common/boosterpack_connector.dtsi:10 */
		gpio-map = < 0x2 0x0 &gpio0 0x17 0x0 >,
		           < 0x3 0x0 &gpio0 0xc 0x0 >,
		           < 0x4 0x0 &gpio0 0xd 0x0 >,
		           < 0x5 0x0 &gpio0 0x16 0x0 >,
		           < 0x6 0x0 &gpio0 0x18 0x0 >,
		           < 0x7 0x0 &gpio0 0xa 0x0 >,
		           < 0x8 0x0 &gpio0 0x15 0x0 >,
		           < 0x9 0x0 &gpio0 0x4 0x0 >,
		           < 0xa 0x0 &gpio0 0x5 0x0 >,
		           < 0xc 0x0 &gpio0 0xe 0x0 >,
		           < 0xd 0x0 &gpio0 0xf 0x0 >,
		           < 0xe 0x0 &gpio0 0x8 0x0 >,
		           < 0xf 0x0 &gpio0 0x9 0x0 >,
		           < 0x12 0x0 &gpio0 0xb 0x0 >,
		           < 0x13 0x0 &gpio0 0x3 0x0 >,
		           < 0x17 0x0 &gpio0 0x19 0x0 >,
		           < 0x18 0x0 &gpio0 0x1a 0x0 >,
		           < 0x19 0x0 &gpio0 0x1b 0x0 >,
		           < 0x1a 0x0 &gpio0 0x1c 0x0 >,
		           < 0x1b 0x0 &gpio0 0x1d 0x0 >,
		           < 0x1c 0x0 &gpio0 0x1e 0x0 >,
		           < 0x1f 0x0 &gpio0 0x11 0x0 >,
		           < 0x20 0x0 &gpio0 0x10 0x0 >,
		           < 0x24 0x0 &gpio0 0x12 0x0 >,
		           < 0x25 0x0 &gpio0 0x13 0x0 >,
		           < 0x26 0x0 &gpio0 0x14 0x0 >,
		           < 0x27 0x0 &gpio0 0x6 0x0 >,
		           < 0x28 0x0 &gpio0 0x7 0x0 >;  /* in zephyr/boards/ti/common/boosterpack_connector.dtsi:11 */
	};

	/* node '/leds' defined in zephyr/boards/ti/common/launchxl.dtsi:33 */
	leds {
		compatible = "gpio-leds"; /* in zephyr/boards/ti/common/launchxl.dtsi:34 */

		/* node '/leds/led_0' defined in zephyr/boards/ti/common/launchxl.dtsi:35 */
		led0: led_0 {
			gpios = < &gpio0 0x7 0x0 >; /* in zephyr/boards/ti/common/launchxl.dtsi:36 */
			label = "Green LED";        /* in zephyr/boards/ti/common/launchxl.dtsi:37 */
		};

		/* node '/leds/led_1' defined in zephyr/boards/ti/common/launchxl.dtsi:39 */
		led1: led_1 {
			gpios = < &gpio0 0x6 0x0 >; /* in zephyr/boards/ti/common/launchxl.dtsi:40 */
			label = "Red LED";          /* in zephyr/boards/ti/common/launchxl.dtsi:41 */
		};
	};

	/* node '/keys' defined in zephyr/boards/ti/common/launchxl.dtsi:45 */
	keys {
		compatible = "gpio-keys"; /* in zephyr/boards/ti/common/launchxl.dtsi:46 */

		/* node '/keys/btn_0' defined in zephyr/boards/ti/common/launchxl.dtsi:47 */
		btn0: btn_0 {
			gpios = < &gpio0 0xf 0x11 >; /* in zephyr/boards/ti/common/launchxl.dtsi:48 */
			label = "Push button 1";     /* in zephyr/boards/ti/common/launchxl.dtsi:49 */
			zephyr,code = < 0xb >;       /* in zephyr/boards/ti/common/launchxl.dtsi:50 */
		};

		/* node '/keys/btn_1' defined in zephyr/boards/ti/common/launchxl.dtsi:52 */
		btn1: btn_1 {
			gpios = < &gpio0 0xe 0x11 >; /* in zephyr/boards/ti/common/launchxl.dtsi:53 */
			label = "Push button 2";     /* in zephyr/boards/ti/common/launchxl.dtsi:54 */
			zephyr,code = < 0x2 >;       /* in zephyr/boards/ti/common/launchxl.dtsi:55 */
		};
	};

	/* node '/antenna_mux0' defined in zephyr/boards/ti/common/launchxl_sky13317.dtsi:21 */
	antenna_mux0: antenna_mux0 {
		compatible = "skyworks,sky13317";                                            /* in zephyr/boards/ti/common/launchxl_sky13317.dtsi:22 */
		status = "okay";                                                             /* in zephyr/boards/ti/common/launchxl_sky13317.dtsi:23 */
		gpios = < &gpio0 0x1c 0x0 >,
		        < &gpio0 0x1d 0x0 >,
		        < &gpio0 0x1e 0x0 >;                                                 /* in zephyr/boards/ti/common/launchxl_sky13317.dtsi:24 */
		pinctrl-0 = < &board_ant_24g_off &board_ant_tx_pa_off &board_ant_subg_off >; /* in zephyr/boards/ti/common/launchxl_sky13317.dtsi:26 */
		pinctrl-1 = < &board_ant_24g_on &board_ant_tx_pa_off &board_ant_subg_off >;  /* in zephyr/boards/ti/common/launchxl_sky13317.dtsi:27 */
		pinctrl-2 = < &board_ant_24g_on &board_ant_tx_pa_on &board_ant_subg_off >;   /* in zephyr/boards/ti/common/launchxl_sky13317.dtsi:28 */
		pinctrl-3 = < &board_ant_24g_off &board_ant_tx_pa_off &board_ant_subg_on >;  /* in zephyr/boards/ti/common/launchxl_sky13317.dtsi:29 */
		pinctrl-4 = < &board_ant_24g_off &board_ant_tx_pa_on &board_ant_subg_on >;   /* in zephyr/boards/ti/common/launchxl_sky13317.dtsi:30 */
		pinctrl-names = "default",
		                "ant_24g",
		                "ant_24g_pa",
		                "ant_subg",
		                "ant_subg_pa";                                               /* in zephyr/boards/ti/common/launchxl_sky13317.dtsi:31 */
	};

	/* node '/switch1' defined in pandora/samples/net/openthread/narada_switch/boards/cc1352p7_lp.overlay:2 */
	switch1 {
		compatible = "narada,switch-gpio"; /* in pandora/samples/net/openthread/narada_switch/boards/cc1352p7_lp.overlay:3 */
		gpios = < &gpio0 0x7 0x0 >;        /* in pandora/samples/net/openthread/narada_switch/boards/cc1352p7_lp.overlay:5 */
	};

	/* node '/switch2' defined in pandora/samples/net/openthread/narada_switch/boards/cc1352p7_lp.overlay:8 */
	switch2 {
		compatible = "narada,switch-gpio"; /* in pandora/samples/net/openthread/narada_switch/boards/cc1352p7_lp.overlay:9 */
		gpios = < &gpio0 0x6 0x0 >;        /* in pandora/samples/net/openthread/narada_switch/boards/cc1352p7_lp.overlay:11 */
	};
};
